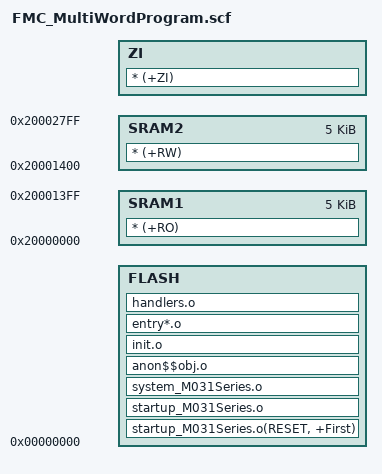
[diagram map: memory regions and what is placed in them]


FLASH 0x00000000 0x00002000
{
    FLASH +0
    {
         startup_M031Series.o(RESET, +First)
         startup_M031Series.o
         system_M031Series.o
         anon$$obj.o
         init.o
         entry*.o
         handlers.o
    }

    SRAM1 0x20000000 0x00001400
    {  
        * (+RO)
    }

    SRAM2 0x20001400 0x00001400
    {
        * (+RW)
    
    }

    ZI +0
    {
        * (+ZI)
    }
}
